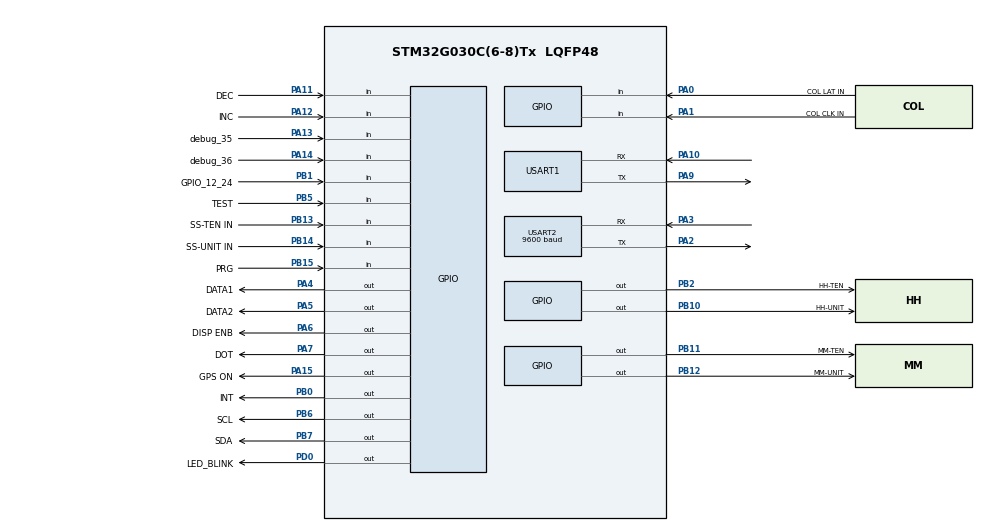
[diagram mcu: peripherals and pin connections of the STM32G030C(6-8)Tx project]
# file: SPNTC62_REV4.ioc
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Mcu.Family=STM32G0
Mcu.Name=STM32G030C(6-8)Tx
Mcu.Package=LQFP48
NVIC.FLASH_IRQn=true\:0\:0\:false\:true\:true\:2\:true\:true\:true
NVIC.RCC_IRQn=true\:0\:0\:false\:true\:true\:3\:true\:false\:true
NVIC.USART1_IRQn=true\:0\:0\:false\:true\:true\:4\:true\:true\:true
NVIC.USART2_IRQn=true\:0\:0\:false\:true\:true\:5\:true\:true\:true
NVIC.WWDG_IRQn=true\:0\:0\:false\:true\:true\:1\:true\:true\:true
PA0.GPIO_Label=COL LAT IN
PA0.Signal=GPIO_Input
PA1.GPIO_Label=COL CLK IN
PA1.Signal=GPIO_Input
PA10.Mode=Asynchronous
PA10.Signal=USART1_RX
PA11\ [PA9].GPIO_Label=DEC
PA11\ [PA9].Signal=GPIO_Input
PA12\ [PA10].GPIO_Label=INC
PA12\ [PA10].Signal=GPIO_Input
PA13.GPIO_Label=debug_35
PA13.Signal=GPIO_Input
PA14-BOOT0.GPIO_Label=debug_36
PA14-BOOT0.Signal=GPIO_Input
PA15.GPIO_Label=GPS ON
PA15.Signal=GPIO_Output
PA2.Mode=Asynchronous
PA2.Signal=USART2_TX
PA3.Mode=Asynchronous
PA3.Signal=USART2_RX
PA4.GPIO_Label=DATA1
PA4.Signal=GPIO_Output
PA5.GPIO_Label=DATA2
PA5.Signal=GPIO_Output
PA6.GPIO_Label=DISP ENB
PA6.Signal=GPIO_Output
PA7.GPIO_Label=DOT
PA7.Signal=GPIO_Output
PA9.Mode=Asynchronous
PA9.Signal=USART1_TX
PB0.GPIO_Label=INT
PB0.Signal=GPIO_Output
PB1.GPIO_Label=GPIO_12_24
PB1.Signal=GPIO_Input
PB10.GPIO_Label=HH-UNIT
PB10.Signal=GPIO_Output
PB11.GPIO_Label=MM-TEN
PB11.Signal=GPIO_Output
PB12.GPIO_Label=MM-UNIT
PB12.Signal=GPIO_Output
PB13.GPIO_Label=SS-TEN IN
PB13.Signal=GPIO_Input
PB14.GPIO_Label=SS-UNIT IN
PB14.Signal=GPIO_Input
PB15.GPIO_Label=PRG
PB15.Signal=GPIO_Input
PB2.GPIO_Label=HH-TEN
PB2.Signal=GPIO_Output
PB5.GPIO_Label=TEST
PB5.Signal=GPIO_Input
PB6.GPIO_Label=SCL
PB6.Signal=GPIO_Output
PB7.GPIO_Label=SDA
PB7.Signal=GPIO_Output
PD0.GPIO_Label=LED_BLINK
PD0.Signal=GPIO_Output
PF0-OSC_IN\ (PF0).Mode=HSE-External-Oscillator
PF0-OSC_IN\ (PF0).Signal=RCC_OSC_IN
PF1-OSC_OUT\ (PF1).Mode=HSE-External-Oscillator
PF1-OSC_OUT\ (PF1).Signal=RCC_OSC_OUT
ProjectManager.HeapSize=0x200
ProjectManager.StackSize=0x400
ProjectManager.TargetToolchain=EWARM V8.50
RCC.AHBFreq_Value=16000000
RCC.CortexFreq_Value=16000000
RCC.EXTERNAL_CLOCK_VALUE=12288000
RCC.HCLKFreq_Value=16000000
RCC.HSE_VALUE=8000000
RCC.HSI_VALUE=16000000
RCC.LSE_VALUE=32768
RCC.SYSCLKFreq_VALUE=16000000
RCC.VCOOutputFreq_Value=128000000
USART1.VirtualMode-Asynchronous=VM_ASYNC
USART2.BaudRate=9600
USART2.VirtualMode-Asynchronous=VM_ASYNC
VP_RTC_VS_RTC_Activate.Mode=RTC_Enabled
VP_WWDG_VS_WWDG.Mode=WWDG_Activate
board=custom

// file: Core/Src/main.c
/* USER CODE BEGIN Header */
/**
  ******************************************************************************
  * @file           : main.c
  * @brief          : Main program body
  ******************************************************************************
  * @attention
  *
  * Copyright (c) 2024 STMicroelectronics.
  * All rights reserved.
  *
  * This software is licensed under terms that can be found in the LICENSE file
  * in the root directory of this software component.
  * If no LICENSE file comes with this software, it is provided AS-IS.
  *
  ******************************************************************************
  */
/* USER CODE END Header */
#include "main.h"

void SystemClock_Config(void);
static void MX_GPIO_Init(void);
static void MX_RTC_Init(void);
static void MX_USART1_UART_Init(void);
static void MX_USART2_UART_Init(void);
static void MX_WWDG_Init(void);
static void MX_NVIC_Init(void);

int main(void)
{

  /* MCU Configuration--------------------------------------------------------*/

  /* Reset of all peripherals, Initializes the Flash interface and the Systick. */
  HAL_Init();

  /* Configure the system clock */
  SystemClock_Config();

  /* Initialize all configured peripherals */
  MX_GPIO_Init();
  MX_RTC_Init();
  MX_USART1_UART_Init();
  MX_USART2_UART_Init();
  MX_WWDG_Init();

  /* Initialize interrupts */
  MX_NVIC_Init();

  /* Infinite loop */
  /* USER CODE BEGIN WHILE */
  while (1)
  {
    Key_Entry = Key_Scan();

    switch (key_Entry)
  case 1:

   /*Extract time from the nmea string*/

    {

    /* USER CODE END WHILE */

  }
}

void SystemClock_Config(void)
{
  /* HSI configuration and activation */
  LL_RCC_HSI_Enable();
  while(LL_RCC_HSI_IsReady() != 1)
  {
  }

  /* LSI configuration and activation */
  LL_RCC_LSI_Enable();
  while(LL_RCC_LSI_IsReady() != 1)
  {
  }

  LL_PWR_EnableBkUpAccess();
  /* Set AHB prescaler*/
  LL_RCC_SetAHBPrescaler(LL_RCC_SYSCLK_DIV_1);

  /* Sysclk activation on the HSI */
  LL_RCC_SetSysClkSource(LL_RCC_SYS_CLKSOURCE_HSI);
  while(LL_RCC_GetSysClkSource() != LL_RCC_SYS_CLKSOURCE_STATUS_HSI)
  {
  }

  /* Set APB1 prescaler*/
  LL_RCC_SetAPB1Prescaler(LL_RCC_APB1_DIV_1);
  /* Update CMSIS variable (which can be updated also through SystemCoreClockUpdate function) */
  LL_SetSystemCoreClock(16000000);

   /* Update the time base */
  if (HAL_InitTick (TICK_INT_PRIORITY) != HAL_OK)
  {
    Error_Handler();
  }
}

/**
  * @brief NVIC Configuration.
  * @retval None
  */
static void MX_NVIC_Init(void)
{
  /* WWDG_IRQn interrupt configuration */
  NVIC_SetPriority(WWDG_IRQn, 0);
  NVIC_EnableIRQ(WWDG_IRQn);
  /* FLASH_IRQn interrupt configuration */
  HAL_NVIC_SetPriority(FLASH_IRQn, 0, 0);
  HAL_NVIC_EnableIRQ(FLASH_IRQn);
  /* RCC_IRQn interrupt configuration */
  NVIC_SetPriority(RCC_IRQn, 0);
  NVIC_EnableIRQ(RCC_IRQn);
  /* USART1_IRQn interrupt configuration */
  NVIC_SetPriority(USART1_IRQn, 0);
  NVIC_EnableIRQ(USART1_IRQn);
  /* USART2_IRQn interrupt configuration */
  NVIC_SetPriority(USART2_IRQn, 0);
  NVIC_EnableIRQ(USART2_IRQn);
}

static void MX_RTC_Init(void)
{

  LL_RTC_InitTypeDef RTC_InitStruct = {0};

  if(LL_RCC_GetRTCClockSource() != LL_RCC_RTC_CLKSOURCE_LSI)
  {
    LL_RCC_ForceBackupDomainReset();
    LL_RCC_ReleaseBackupDomainReset();
    LL_RCC_SetRTCClockSource(LL_RCC_RTC_CLKSOURCE_LSI);
  }

  /* Peripheral clock enable */
  LL_RCC_EnableRTC();
  LL_APB1_GRP1_EnableClock(LL_APB1_GRP1_PERIPH_RTC);

  RTC_InitStruct.HourFormat = LL_RTC_HOURFORMAT_24HOUR;
  RTC_InitStruct.AsynchPrescaler = 127;
  RTC_InitStruct.SynchPrescaler = 255;
  LL_RTC_Init(RTC, &RTC_InitStruct);

}

static void MX_USART1_UART_Init(void)
{

  LL_USART_InitTypeDef USART_InitStruct = {0};

  LL_GPIO_InitTypeDef GPIO_InitStruct = {0};

  LL_RCC_SetUSARTClockSource(LL_RCC_USART1_CLKSOURCE_PCLK1);

  /* Peripheral clock enable */
  LL_APB2_GRP1_EnableClock(LL_APB2_GRP1_PERIPH_USART1);

  LL_IOP_GRP1_EnableClock(LL_IOP_GRP1_PERIPH_GPIOA);
  /**USART1 GPIO Configuration
  PA9   ------> USART1_TX
  PA10   ------> USART1_RX
  */
  GPIO_InitStruct.Pin = LL_GPIO_PIN_9;
  GPIO_InitStruct.Mode = LL_GPIO_MODE_ALTERNATE;
  GPIO_InitStruct.Speed = LL_GPIO_SPEED_FREQ_LOW;
  GPIO_InitStruct.OutputType = LL_GPIO_OUTPUT_PUSHPULL;
  GPIO_InitStruct.Pull = LL_GPIO_PULL_NO;
  GPIO_InitStruct.Alternate = LL_GPIO_AF_1;
  LL_GPIO_Init(GPIOA, &GPIO_InitStruct);

  GPIO_InitStruct.Pin = LL_GPIO_PIN_10;
  GPIO_InitStruct.Mode = LL_GPIO_MODE_ALTERNATE;
  GPIO_InitStruct.Speed = LL_GPIO_SPEED_FREQ_LOW;
  GPIO_InitStruct.OutputType = LL_GPIO_OUTPUT_PUSHPULL;
  GPIO_InitStruct.Pull = LL_GPIO_PULL_NO;
  GPIO_InitStruct.Alternate = LL_GPIO_AF_1;
  LL_GPIO_Init(GPIOA, &GPIO_InitStruct);

  USART_InitStruct.PrescalerValue = LL_USART_PRESCALER_DIV1;
  USART_InitStruct.BaudRate = 115200;
  USART_InitStruct.DataWidth = LL_USART_DATAWIDTH_8B;
  USART_InitStruct.StopBits = LL_USART_STOPBITS_1;
  USART_InitStruct.Parity = LL_USART_PARITY_NONE;
  USART_InitStruct.TransferDirection = LL_USART_DIRECTION_TX_RX;
  USART_InitStruct.HardwareFlowControl = LL_USART_HWCONTROL_NONE;
  USART_InitStruct.OverSampling = LL_USART_OVERSAMPLING_16;
  LL_USART_Init(USART1, &USART_InitStruct);
  LL_USART_SetTXFIFOThreshold(USART1, LL_USART_FIFOTHRESHOLD_1_8);
  LL_USART_SetRXFIFOThreshold(USART1, LL_USART_FIFOTHRESHOLD_1_8);
  LL_USART_DisableFIFO(USART1);
  LL_USART_ConfigAsyncMode(USART1);

  LL_USART_Enable(USART1);

  /* Polling USART1 initialisation */
  while((!(LL_USART_IsActiveFlag_TEACK(USART1))) || (!(LL_USART_IsActiveFlag_REACK(USART1))))
  {
  }

}

static void MX_USART2_UART_Init(void)
{

  LL_USART_InitTypeDef USART_InitStruct = {0};

  LL_GPIO_InitTypeDef GPIO_InitStruct = {0};

  /* Peripheral clock enable */
  LL_APB1_GRP1_EnableClock(LL_APB1_GRP1_PERIPH_USART2);

  LL_IOP_GRP1_EnableClock(LL_IOP_GRP1_PERIPH_GPIOA);
  /**USART2 GPIO Configuration
  PA2   ------> USART2_TX
  PA3   ------> USART2_RX
  */
  GPIO_InitStruct.Pin = LL_GPIO_PIN_2;
  GPIO_InitStruct.Mode = LL_GPIO_MODE_ALTERNATE;
  GPIO_InitStruct.Speed = LL_GPIO_SPEED_FREQ_LOW;
  GPIO_InitStruct.OutputType = LL_GPIO_OUTPUT_PUSHPULL;
  GPIO_InitStruct.Pull = LL_GPIO_PULL_NO;
  GPIO_InitStruct.Alternate = LL_GPIO_AF_1;
  LL_GPIO_Init(GPIOA, &GPIO_InitStruct);

  GPIO_InitStruct.Pin = LL_GPIO_PIN_3;
  GPIO_InitStruct.Mode = LL_GPIO_MODE_ALTERNATE;
  GPIO_InitStruct.Speed = LL_GPIO_SPEED_FREQ_LOW;
  GPIO_InitStruct.OutputType = LL_GPIO_OUTPUT_PUSHPULL;
  GPIO_InitStruct.Pull = LL_GPIO_PULL_NO;
  GPIO_InitStruct.Alternate = LL_GPIO_AF_1;
  LL_GPIO_Init(GPIOA, &GPIO_InitStruct);

  USART_InitStruct.PrescalerValue = LL_USART_PRESCALER_DIV1;
  USART_InitStruct.BaudRate = 9600;
  USART_InitStruct.DataWidth = LL_USART_DATAWIDTH_8B;
  USART_InitStruct.StopBits = LL_USART_STOPBITS_1;
  USART_InitStruct.Parity = LL_USART_PARITY_NONE;
  USART_InitStruct.TransferDirection = LL_USART_DIRECTION_TX_RX;
  USART_InitStruct.HardwareFlowControl = LL_USART_HWCONTROL_NONE;
  USART_InitStruct.OverSampling = LL_USART_OVERSAMPLING_16;
  LL_USART_Init(USART2, &USART_InitStruct);
  LL_USART_ConfigAsyncMode(USART2);

  LL_USART_Enable(USART2);

  /* Polling USART2 initialisation */
  while((!(LL_USART_IsActiveFlag_TEACK(USART2))) || (!(LL_USART_IsActiveFlag_REACK(USART2))))
  {
  }

}

static void MX_WWDG_Init(void)
{

  /* Peripheral clock enable */
  LL_APB1_GRP1_EnableClock(LL_APB1_GRP1_PERIPH_WWDG);

  LL_WWDG_SetCounter(WWDG, 64);
  LL_WWDG_Enable(WWDG);
  LL_WWDG_SetPrescaler(WWDG, LL_WWDG_PRESCALER_1);
  LL_WWDG_SetWindow(WWDG, 64);

}

static void MX_GPIO_Init(void)
{
  LL_GPIO_InitTypeDef GPIO_InitStruct = {0};

  /* GPIO Ports Clock Enable */
  LL_IOP_GRP1_EnableClock(LL_IOP_GRP1_PERIPH_GPIOF);
  LL_IOP_GRP1_EnableClock(LL_IOP_GRP1_PERIPH_GPIOA);
  LL_IOP_GRP1_EnableClock(LL_IOP_GRP1_PERIPH_GPIOB);
  LL_IOP_GRP1_EnableClock(LL_IOP_GRP1_PERIPH_GPIOD);

  /**/
  LL_GPIO_ResetOutputPin(DATA1_GPIO_Port, DATA1_Pin);

  /**/
  LL_GPIO_ResetOutputPin(DATA2_GPIO_Port, DATA2_Pin);

  /**/
  LL_GPIO_ResetOutputPin(DISP_ENB_GPIO_Port, DISP_ENB_Pin);

  /**/
  LL_GPIO_ResetOutputPin(DOT_GPIO_Port, DOT_Pin);

  /**/
  LL_GPIO_ResetOutputPin(INT_GPIO_Port, INT_Pin);

  /**/
  LL_GPIO_ResetOutputPin(HH_TEN_GPIO_Port, HH_TEN_Pin);

  /**/
  LL_GPIO_ResetOutputPin(HH_UNIT_GPIO_Port, HH_UNIT_Pin);

  /**/
  LL_GPIO_ResetOutputPin(MM_TEN_GPIO_Port, MM_TEN_Pin);

  /**/
  LL_GPIO_ResetOutputPin(MM_UNIT_GPIO_Port, MM_UNIT_Pin);

  /**/
  LL_GPIO_ResetOutputPin(GPS_ON_GPIO_Port, GPS_ON_Pin);

  /**/
  LL_GPIO_ResetOutputPin(LED_BLINK_GPIO_Port, LED_BLINK_Pin);

  /**/
  LL_GPIO_ResetOutputPin(SCL_GPIO_Port, SCL_Pin);

  /**/
  LL_GPIO_ResetOutputPin(SDA_GPIO_Port, SDA_Pin);

  /**/
  GPIO_InitStruct.Pin = COL_LAT_IN_Pin;
  GPIO_InitStruct.Mode = LL_GPIO_MODE_INPUT;
  GPIO_InitStruct.Pull = LL_GPIO_PULL_NO;
  LL_GPIO_Init(COL_LAT_IN_GPIO_Port, &GPIO_InitStruct);

  /**/
  GPIO_InitStruct.Pin = COL_CLK_IN_Pin;
  GPIO_InitStruct.Mode = LL_GPIO_MODE_INPUT;
  GPIO_InitStruct.Pull = LL_GPIO_PULL_NO;
  LL_GPIO_Init(COL_CLK_IN_GPIO_Port, &GPIO_InitStruct);

  /**/
  GPIO_InitStruct.Pin = DATA1_Pin;
  GPIO_InitStruct.Mode = LL_GPIO_MODE_OUTPUT;
  GPIO_InitStruct.Speed = LL_GPIO_SPEED_FREQ_LOW;
  GPIO_InitStruct.OutputType = LL_GPIO_OUTPUT_PUSHPULL;
  GPIO_InitStruct.Pull = LL_GPIO_PULL_NO;
  LL_GPIO_Init(DATA1_GPIO_Port, &GPIO_InitStruct);

  /**/
  GPIO_InitStruct.Pin = DATA2_Pin;
  GPIO_InitStruct.Mode = LL_GPIO_MODE_OUTPUT;
  GPIO_InitStruct.Speed = LL_GPIO_SPEED_FREQ_LOW;
  GPIO_InitStruct.OutputType = LL_GPIO_OUTPUT_PUSHPULL;
  GPIO_InitStruct.Pull = LL_GPIO_PULL_NO;
  LL_GPIO_Init(DATA2_GPIO_Port, &GPIO_InitStruct);

  /**/
  GPIO_InitStruct.Pin = DISP_ENB_Pin;
  GPIO_InitStruct.Mode = LL_GPIO_MODE_OUTPUT;
  GPIO_InitStruct.Speed = LL_GPIO_SPEED_FREQ_LOW;
  GPIO_InitStruct.OutputType = LL_GPIO_OUTPUT_PUSHPULL;
  GPIO_InitStruct.Pull = LL_GPIO_PULL_NO;
  LL_GPIO_Init(DISP_ENB_GPIO_Port, &GPIO_InitStruct);

  /**/
  GPIO_InitStruct.Pin = DOT_Pin;
  GPIO_InitStruct.Mode = LL_GPIO_MODE_OUTPUT;
  GPIO_InitStruct.Speed = LL_GPIO_SPEED_FREQ_LOW;
  GPIO_InitStruct.OutputType = LL_GPIO_OUTPUT_PUSHPULL;
  GPIO_InitStruct.Pull = LL_GPIO_PULL_NO;
  LL_GPIO_Init(DOT_GPIO_Port, &GPIO_InitStruct);

  /**/
  GPIO_InitStruct.Pin = INT_Pin;
  GPIO_InitStruct.Mode = LL_GPIO_MODE_OUTPUT;
  GPIO_InitStruct.Speed = LL_GPIO_SPEED_FREQ_LOW;
  GPIO_InitStruct.OutputType = LL_GPIO_OUTPUT_PUSHPULL;
  GPIO_InitStruct.Pull = LL_GPIO_PULL_NO;
  LL_GPIO_Init(INT_GPIO_Port, &GPIO_InitStruct);

  /**/
  GPIO_InitStruct.Pin = GPIO_12_24_Pin;
  GPIO_InitStruct.Mode = LL_GPIO_MODE_INPUT;
  GPIO_InitStruct.Pull = LL_GPIO_PULL_NO;
  LL_GPIO_Init(GPIO_12_24_GPIO_Port, &GPIO_InitStruct);

  /**/
  GPIO_InitStruct.Pin = HH_TEN_Pin;
  GPIO_InitStruct.Mode = LL_GPIO_MODE_OUTPUT;
  GPIO_InitStruct.Speed = LL_GPIO_SPEED_FREQ_LOW;
  GPIO_InitStruct.OutputType = LL_GPIO_OUTPUT_PUSHPULL;
  GPIO_InitStruct.Pull = LL_GPIO_PULL_NO;
  LL_GPIO_Init(HH_TEN_GPIO_Port, &GPIO_InitStruct);

  /**/
  GPIO_InitStruct.Pin = HH_UNIT_Pin;
  GPIO_InitStruct.Mode = LL_GPIO_MODE_OUTPUT;
  GPIO_InitStruct.Speed = LL_GPIO_SPEED_FREQ_LOW;
  GPIO_InitStruct.OutputType = LL_GPIO_OUTPUT_PUSHPULL;
  GPIO_InitStruct.Pull = LL_GPIO_PULL_NO;
  LL_GPIO_Init(HH_UNIT_GPIO_Port, &GPIO_InitStruct);

  /**/
  GPIO_InitStruct.Pin = MM_TEN_Pin;
  GPIO_InitStruct.Mode = LL_GPIO_MODE_OUTPUT;
  GPIO_InitStruct.Speed = LL_GPIO_SPEED_FREQ_LOW;
  GPIO_InitStruct.OutputType = LL_GPIO_OUTPUT_PUSHPULL;
  GPIO_InitStruct.Pull = LL_GPIO_PULL_NO;
  LL_GPIO_Init(MM_TEN_GPIO_Port, &GPIO_InitStruct);

  /**/
  GPIO_InitStruct.Pin = MM_UNIT_Pin;
  GPIO_InitStruct.Mode = LL_GPIO_MODE_OUTPUT;
  GPIO_InitStruct.Speed = LL_GPIO_SPEED_FREQ_LOW;
  GPIO_InitStruct.OutputType = LL_GPIO_OUTPUT_PUSHPULL;
  GPIO_InitStruct.Pull = LL_GPIO_PULL_NO;
  LL_GPIO_Init(MM_UNIT_GPIO_Port, &GPIO_InitStruct);

  /**/
  GPIO_InitStruct.Pin = SS_TEN_IN_Pin;
  GPIO_InitStruct.Mode = LL_GPIO_MODE_INPUT;
  GPIO_InitStruct.Pull = LL_GPIO_PULL_NO;
  LL_GPIO_Init(SS_TEN_IN_GPIO_Port, &GPIO_InitStruct);

  /**/
  GPIO_InitStruct.Pin = SS_UNIT_IN_Pin;
  GPIO_InitStruct.Mode = LL_GPIO_MODE_INPUT;
  GPIO_InitStruct.Pull = LL_GPIO_PULL_NO;
  LL_GPIO_Init(SS_UNIT_IN_GPIO_Port, &GPIO_InitStruct);

  /**/
  GPIO_InitStruct.Pin = PRG_Pin;
  GPIO_InitStruct.Mode = LL_GPIO_MODE_INPUT;
  GPIO_InitStruct.Pull = LL_GPIO_PULL_NO;
  LL_GPIO_Init(PRG_GPIO_Port, &GPIO_InitStruct);

  /**/
  GPIO_InitStruct.Pin = DEC_Pin;
  GPIO_InitStruct.Mode = LL_GPIO_MODE_INPUT;
  GPIO_InitStruct.Pull = LL_GPIO_PULL_NO;
  LL_GPIO_Init(DEC_GPIO_Port, &GPIO_InitStruct);

  /**/
  GPIO_InitStruct.Pin = INC_Pin;
  GPIO_InitStruct.Mode = LL_GPIO_MODE_INPUT;
  GPIO_InitStruct.Pull = LL_GPIO_PULL_NO;
  LL_GPIO_Init(INC_GPIO_Port, &GPIO_InitStruct);

  /**/
  GPIO_InitStruct.Pin = debug_35_Pin;
  GPIO_InitStruct.Mode = LL_GPIO_MODE_INPUT;
  GPIO_InitStruct.Pull = LL_GPIO_PULL_NO;
  LL_GPIO_Init(debug_35_GPIO_Port, &GPIO_InitStruct);

  /**/
  GPIO_InitStruct.Pin = debug_36_Pin;
  GPIO_InitStruct.Mode = LL_GPIO_MODE_INPUT;
  GPIO_InitStruct.Pull = LL_GPIO_PULL_NO;
  LL_GPIO_Init(debug_36_GPIO_Port, &GPIO_InitStruct);

  /**/
  GPIO_InitStruct.Pin = GPS_ON_Pin;
  GPIO_InitStruct.Mode = LL_GPIO_MODE_OUTPUT;
  GPIO_InitStruct.Speed = LL_GPIO_SPEED_FREQ_LOW;
  GPIO_InitStruct.OutputType = LL_GPIO_OUTPUT_PUSHPULL;
  GPIO_InitStruct.Pull = LL_GPIO_PULL_NO;
  LL_GPIO_Init(GPS_ON_GPIO_Port, &GPIO_InitStruct);

  /**/
  GPIO_InitStruct.Pin = LED_BLINK_Pin;
  GPIO_InitStruct.Mode = LL_GPIO_MODE_OUTPUT;
  GPIO_InitStruct.Speed = LL_GPIO_SPEED_FREQ_LOW;
  GPIO_InitStruct.OutputType = LL_GPIO_OUTPUT_PUSHPULL;
  GPIO_InitStruct.Pull = LL_GPIO_PULL_NO;
  LL_GPIO_Init(LED_BLINK_GPIO_Port, &GPIO_InitStruct);

  /**/
  GPIO_InitStruct.Pin = TEST_Pin;
  GPIO_InitStruct.Mode = LL_GPIO_MODE_INPUT;
  GPIO_InitStruct.Pull = LL_GPIO_PULL_NO;
  LL_GPIO_Init(TEST_GPIO_Port, &GPIO_InitStruct);

  /**/
  GPIO_InitStruct.Pin = SCL_Pin;
  GPIO_InitStruct.Mode = LL_GPIO_MODE_OUTPUT;
  GPIO_InitStruct.Speed = LL_GPIO_SPEED_FREQ_LOW;
  GPIO_InitStruct.OutputType = LL_GPIO_OUTPUT_PUSHPULL;
  GPIO_InitStruct.Pull = LL_GPIO_PULL_NO;
  LL_GPIO_Init(SCL_GPIO_Port, &GPIO_InitStruct);

  /**/
  GPIO_InitStruct.Pin = SDA_Pin;
  GPIO_InitStruct.Mode = LL_GPIO_MODE_OUTPUT;
  GPIO_InitStruct.Speed = LL_GPIO_SPEED_FREQ_LOW;
  GPIO_InitStruct.OutputType = LL_GPIO_OUTPUT_PUSHPULL;
  GPIO_InitStruct.Pull = LL_GPIO_PULL_NO;
  LL_GPIO_Init(SDA_GPIO_Port, &GPIO_InitStruct);

}

void Error_Handler(void)
{
  __disable_irq();
  while (1)
  {
  }
}
